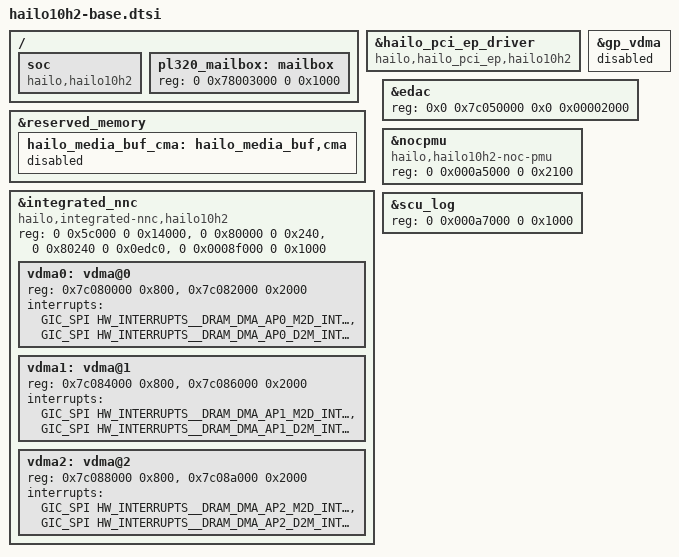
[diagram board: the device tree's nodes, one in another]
// SPDX-License-Identifier:     GPL-2.0
/*
 * Copyright (c) 2019-2024 Hailo Technologies Ltd. All rights reserved.
 */

#define HAILO_SOC_TYPE HAILO_SOC_HAILO10H2
#include "hailo1x-base.dtsi"

/ {
    soc {
        compatible = "hailo,hailo10h2";
    };

    pl320_mailbox: mailbox {
        reg = <0 0x78003000 0 0x1000>;
    };
};

&hailo_pci_ep_driver {
    compatible = "hailo,hailo_pci_ep,hailo10h2";
    status = "okay";
};

&reserved_memory {
    hailo_media_buf_cma: hailo_media_buf,cma {
        status = "disabled";
    };
};

&integrated_nnc {
    compatible = "hailo,integrated-nnc,hailo10h2";
    reg = <0 0x5c000 0 0x14000>, <0 0x80000 0 0x240>, <0 0x80240 0 0x0edc0>, <0 0x0008f000 0 0x1000>;
    reg-names = "core-fw-code", "core-fw-isr-vector", "core-fw-data", "core-fw-log";
    vdma0: vdma@0 {
        reg = <0x7c080000 0x800>, <0x7c082000 0x2000>;
        reg-names = "channel-regs", "engine-regs";
        interrupts = <GIC_SPI HW_INTERRUPTS__DRAM_DMA_AP0_M2D_INT_IRQ IRQ_TYPE_LEVEL_HIGH>,
                     <GIC_SPI HW_INTERRUPTS__DRAM_DMA_AP0_D2M_INT_IRQ IRQ_TYPE_LEVEL_HIGH>;
        interrupt-names = "input", "output";
    };

    vdma1: vdma@1 {
        reg = <0x7c084000 0x800>, <0x7c086000 0x2000>;
        reg-names = "channel-regs", "engine-regs";
        interrupts = <GIC_SPI HW_INTERRUPTS__DRAM_DMA_AP1_M2D_INT_IRQ IRQ_TYPE_LEVEL_HIGH>,
                     <GIC_SPI HW_INTERRUPTS__DRAM_DMA_AP1_D2M_INT_IRQ IRQ_TYPE_LEVEL_HIGH>;
        interrupt-names = "input", "output";
    };

    vdma2: vdma@2 {
        reg = <0x7c088000 0x800>, <0x7c08a000 0x2000>;
        reg-names = "channel-regs", "engine-regs";
        interrupts = <GIC_SPI HW_INTERRUPTS__DRAM_DMA_AP2_M2D_INT_IRQ IRQ_TYPE_LEVEL_HIGH>,
                     <GIC_SPI HW_INTERRUPTS__DRAM_DMA_AP2_D2M_INT_IRQ IRQ_TYPE_LEVEL_HIGH>;
        interrupt-names = "input", "output";
    };
};

&gp_vdma {
    status = "disabled";
};

&edac {
    reg = <0x0 0x7c050000 0x0 0x00002000>;
};

&nocpmu {
    compatible = "hailo,hailo10h2-noc-pmu";
    reg = <0 0x000a5000 0 0x2100>;
};

&scu_log {
    reg = <0 0x000a7000 0 0x1000>;
};

/delete-node/ &cpu_2;
/delete-node/ &cpu_3;
